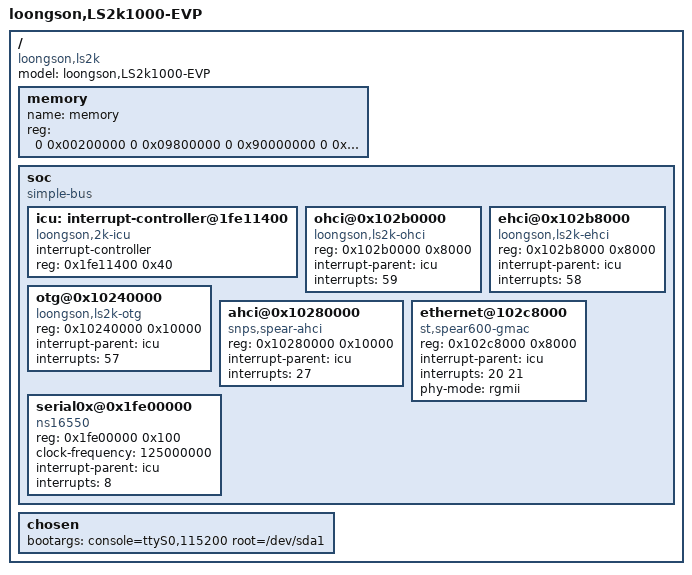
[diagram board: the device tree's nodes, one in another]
/*
 * 2K1000 Device Tree Source for LS2K1000 boards
 */

/dts-v1/;
/ {
	model = "loongson,LS2k1000-EVP";
	compatible = "loongson,ls2k";
	#address-cells = <2>;
	#size-cells = <2>;

	// Since 2K1000 support > 4GiB DIMM, use 2 cell for and address size
	memory {
		name = "memory";
		device_type = "memory";
		reg =  <0 0x00200000 0 0x09800000	// 152MiB at 2MiB
			0 0x90000000 0 0x70000000>;	// 1792MiB at 2304MiB
	};

	// all soc device use 32bit address

	soc {
		compatible = "simple-bus";
		#address-cells = <1>;
		#size-cells = <1>;
		ranges = <0x10000000 0 0x10000000 0x10000000>;

		icu: interrupt-controller@1fe11400 {
			compatible = "loongson,2k-icu";
			interrupt-controller;
			#interrupt-cells = <1>;
			reg = <0x1fe11400 0x40>;
		};

		ohci@0x102b0000 {
			compatible = "loongson,ls2k-ohci", "usb-ohci";
			reg = <0x102b0000 0x8000>;
			interrupt-parent = <&icu>;
			interrupts = <59>;
		};

		ehci@0x102b8000 {
			compatible = "loongson,ls2k-ehci", "usb-ehci";
			reg = <0x102b8000 0x8000>;
			interrupt-parent = <&icu>;
			interrupts = <58>;
		};

		otg@0x10240000 {
			compatible = "loongson,ls2k-otg", "usb-otg";
			reg = <0x10240000 0x10000>;
			interrupt-parent = <&icu>;
			interrupts = <57>;
		};

		ahci@0x10280000 {
			compatible = "snps,spear-ahci";
			reg = <0x10280000 0x10000>;
			interrupt-parent = <&icu>;
			interrupts = <27>;
		};

		ethernet@102c8000 {
			compatible = "st,spear600-gmac";
			reg = <0x102c8000 0x8000>;
			interrupt-parent = <&icu>;
			interrupts = <20 21>;
			interrupt-names = "macirq", "eth_wake_irq";
			phy-mode = "rgmii";
		};

		/*ethernet@102c0000 {*/
			/*compatible = "st,spear600-gmac";*/
			/*reg = <0x102c0000 0x8000>;*/
			/*interrupt-parent = <&icu>;*/
			/*interrupts = <22 23>;*/
			/*interrupt-names = "macirq", "eth_wake_irq";*/
			/*phy-mode = "rgmii";*/
		/*};*/

		serial0x@0x1fe00000{
			device_type = "serial";
			compatible = "ns16550";
			reg = <0x1fe00000 0x100>;
			clock-frequency = <125000000>;
			interrupt-parent = <&icu>;
			interrupts = <8>;
		};
	};

	chosen {
		bootargs = "console=ttyS0,115200 root=/dev/sda1";
	};
};
